AUTOSAR XML (schema 4-2-2)
package /Components
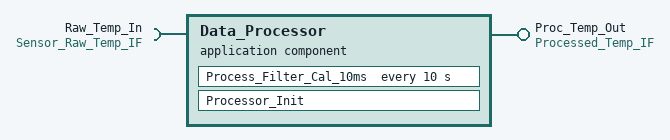
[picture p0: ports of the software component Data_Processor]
  application sw component type Data_Processor
    provide port Proc_Temp_Out: provided-interface=Processed_Temp_IF
    require port Raw_Temp_In: required-interface=Sensor_Raw_Temp_IF
    behavior Data_Processor_InternalBehavior
      init event Processor_Init_Event: start-on-event=Processor_Init
      timing event Processor_10ms_Event: start-on-event=Process_Filter_Cal_10ms, period=10
      runnable Processor_Init: symbol=Data_Processor_Init
      runnable Process_Filter_Cal_10ms: minimum-start-interval=10, symbol=Data_Processor_Process_Filter_Cal_10ms
        data-receive-point-by-arguments:
          access VA_Temp{1..3}_Raw_In: accessed-variable=Raw_Temp_In.Temp{1..3}_Raw
        data-send-points:
          access VA_Temp{1..3}_Proc_Out: accessed-variable=Proc_Temp_Out.Temp{1..3}_Proc
